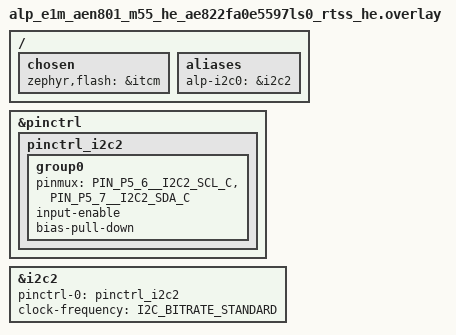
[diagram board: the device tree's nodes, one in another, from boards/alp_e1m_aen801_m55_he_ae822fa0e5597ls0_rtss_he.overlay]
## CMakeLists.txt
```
# SPDX-License-Identifier: Apache-2.0
#
# On-silicon I2C2 + EEPROM validation for the E1M-AEN801 (Alif Ensemble E8),
# scanning the SoC I2C2 DesignWare master bus and reading the on-module 24C128
# EEPROM @0x50 through the UPSTREAM Zephyr i2c_dw driver (Tier-1).  A RAM console
# carries the scan results + EEPROM hexdump + PASS/FAIL line.
#
# Standalone Zephyr app (no alp_project.py board.yaml flow): build with
#   ZEPHYR_BASE=<zephyr-base> west build \
#     -b alp_e1m_aen801_m55_he/ae822fa0e5597ls0/rtss_he <this-dir> -- \
#     "-DEXTRA_ZEPHYR_MODULES=<alp-sdk>;<hal_alif>"
# Zephyr applies boards/<fully-qualified-board>.overlay by itself.

cmake_minimum_required(VERSION 3.20)

find_package(Zephyr REQUIRED HINTS $ENV{ZEPHYR_BASE})
project(aen_i2c2_eeprom_regcheck LANGUAGES C)

target_sources(app PRIVATE src/main.c)
```

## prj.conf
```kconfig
# SPDX-License-Identifier: Apache-2.0
#
# Bench config for the I2C2 + EEPROM RAM-run on the E1M-AEN801 (Alif Ensemble
# E8).
#
# Console is the E1M edge UART0.

# --- Console -----------------------------------------------------------------
# Console: Alp UART console -- E1M edge UART0 (Alif UART5, P3_4/P3_5, 115200
# 8N1, NS16550), the E1M-AEN801 carrier console. The board _defconfig already
# selects it; we set it explicitly here so the example is self-describing.
CONFIG_SERIAL=y
CONFIG_CONSOLE=y
CONFIG_UART_CONSOLE=y
CONFIG_UART_INTERRUPT_DRIVEN=y
# Serial-less bench? Comment the four lines above and uncomment these to read
# 'ram_console_buf' over SWD instead:
# CONFIG_RAM_CONSOLE=y
# CONFIG_RAM_CONSOLE_BUFFER_SIZE=2048
# CONFIG_UART_CONSOLE=n
CONFIG_PRINTK=y

# --- I2C ---------------------------------------------------------------------
# The upstream i2c_dw driver (CONFIG_I2C_DW) self-selects `default y` from the
# okay'd "snps,designware-i2c" i2c2 node, so only the I2C subsystem itself needs
# turning on here.  PINCTRL is pulled in by the i2c2 pinctrl-0; set it for
# clarity.  ALP_SDK is not required for i2c_dw (Tier-1 upstream) -- left off to
# keep the image minimal.
CONFIG_I2C=y
CONFIG_PINCTRL=y

# Keep the image small + deterministic for a RAM-run.
CONFIG_LOG=n
```

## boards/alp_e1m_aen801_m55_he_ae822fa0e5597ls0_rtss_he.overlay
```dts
/*
 * Copyright (c) 2026 Alp Lab AB
 * SPDX-License-Identifier: Apache-2.0
 *
 * On-silicon I2C2 + EEPROM validation overlay for the E1M-AEN801 (Alif Ensemble
 * E8, M55-HE), bench RAM-run via J-Link.
 *
 * Wires the on-module 24C128 EEPROM bus.  The EEPROM's interface is selected by
 * bridge/DNP resistors onto SoC I2C2 (DesignWare master, upstream i2c_dw), pins
 * P5_6 SCL_C / P5_7 SDA_C -- NOT the slave-only LPI2C0 (which carries the
 * RTC/TMP on this board rev and is read-blocked).  Full master read+write via
 * upstream Zephyr's i2c_dw, per ADR 0017 (Tier-1 upstream-native).
 *
 * i2c2 node: i2c@49012000 (compatible "snps,designware-i2c", IRQ 134) per the
 * AE822 DFP device header.
 *
 * The pinctrl group below is copied VERBATIM from the aen-eeprom-manifest
 * overlay -- the input-enable + bias-pull-down pair is BENCH-VALIDATED on the E8
 * (2026-06-15).  Do NOT "correct" bias-pull-down to bias-pull-up: see the
 * group's own comment below for why -- alp-sdk#2046 corrected the reason
 * given here previously (pinctrl_soc.h does not invert the pull-direction
 * encoding).
 */
#include <zephyr/dt-bindings/pinctrl/alif-ensemble-pinctrl.h>
#include <zephyr/dt-bindings/i2c/i2c.h>

/*
 * MANDATORY bench RAM-run retarget: run from ITCM so J-Link can loadbin+run
 * without programming MRAM, and drop the MCUboot code-partition fixup.
 */
/ {
	chosen {
		/* PATH-REFERENCE form (&itcm), NOT the <&itcm> phandle-array form:
		 * the phandle-array form yields CONFIG_FLASH_SIZE=0 and the image
		 * overflows the (empty) FLASH region at link time. */
		zephyr,flash = &itcm;
		/delete-property/ zephyr,code-partition;
	};

	aliases {
		alp-i2c0 = &i2c2;
	};
};

&pinctrl {
	pinctrl_i2c2: pinctrl_i2c2 {
		group0 {
			pinmux = <PIN_P5_6__I2C2_SCL_C>, <PIN_P5_7__I2C2_SDA_C>;
			/* I2C pad config -- BENCH-VALIDATED on the E8 (2026-06-15) and
			 * matching Alif's own reference i2c pinctrl (sdk-alif
			 * common/ensemble-pinctrl.dtsi: read-enable=1 +
			 * driver-state-control=2):
			 *   input-enable    -> pad REN bit: the i2c_dw controller MUST be
			 *                      able to SENSE SDA/SCL or it reads every
			 *                      address as a NACK (no ACK detect). Without
			 *                      this the EEPROM never responds.
			 *   bias-pull-down  -> upstream pinctrl_soc.h encodes the pad
			 *                      driver-state-control (DSC) field as DSC=2
			 *                      from bias-pull-down, a REAL pull-down --
			 *                      exactly Alif's reference value for I2C, and
			 *                      NOT an inverted encoding: pinctrl_soc.h's
			 *                      ALIF_PINCTRL_BIAS_CFG() macro (lines 44-48)
			 *                      maps bias-pull-up -> DSC=1 and
			 *                      bias-pull-down -> DSC=2 unconditionally,
			 *                      matching the field comment at line 24.  A
			 *                      real pull-down is harmless here because the
			 *                      EVK carrier's R137/R144 pull-ups are stuffed
			 *                      on this bus and dominate a weak internal
			 *                      one.  Switching to bias-pull-up was earlier
			 *                      reported to give a dead bus, blamed on that
			 *                      (nonexistent) inversion -- the dead-bus
			 *                      report is therefore UNCONFIRMED, not
			 *                      disproven, absent a fresh bench trial; it is
			 *                      not evidence either way.
			 * Do NOT "correct" bias-pull-down to bias-pull-up: it is the
			 * bench-validated, correct-as-emitted value regardless of which
			 * reading is right (alp-sdk#2046).
			 */
			input-enable;
			bias-pull-down;
		};
	};
};

&i2c2 {
	status = "okay";
	pinctrl-0 = <&pinctrl_i2c2>;
	pinctrl-names = "default";
	/* 100 kHz: bench-validated; the on-module bus has no fast-mode margin
	 * unless external pull-ups are stuffed. */
	clock-frequency = <I2C_BITRATE_STANDARD>;
};
```

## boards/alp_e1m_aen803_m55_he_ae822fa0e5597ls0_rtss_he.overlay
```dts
/*
 * Copyright (c) 2026 Alp Lab AB
 * SPDX-License-Identifier: Apache-2.0
 *
 * On-silicon I2C2 + EEPROM validation overlay for the E1M-AEN803 (Alif Ensemble
 * E8, M55-HE), bench RAM-run via J-Link.
 *
 * Wires the on-module 24C128 EEPROM bus.  The EEPROM's interface is selected by
 * bridge/DNP resistors onto SoC I2C2 (DesignWare master, upstream i2c_dw), pins
 * P5_6 SCL_C / P5_7 SDA_C -- NOT the slave-only LPI2C0 (which carries the
 * RTC/TMP on this board rev and is read-blocked).  Full master read+write via
 * upstream Zephyr's i2c_dw, per ADR 0017 (Tier-1 upstream-native).
 *
 * i2c2 node: i2c@49012000 (compatible "snps,designware-i2c", IRQ 134) per the
 * AE822 DFP device header.
 *
 * The pinctrl group below is copied VERBATIM from the aen-eeprom-manifest
 * overlay -- the input-enable + bias-pull-down pair is BENCH-VALIDATED on the E8
 * (2026-06-15).  Do NOT "correct" bias-pull-down to bias-pull-up: see the
 * group's own comment below for why -- alp-sdk#2046 corrected the reason
 * given here previously (pinctrl_soc.h does not invert the pull-direction
 * encoding).
 */
#include <zephyr/dt-bindings/pinctrl/alif-ensemble-pinctrl.h>
#include <zephyr/dt-bindings/i2c/i2c.h>

/*
 * MANDATORY bench RAM-run retarget: run from ITCM so J-Link can loadbin+run
 * without programming MRAM, and drop the MCUboot code-partition fixup.
 */
/ {
	chosen {
		/* PATH-REFERENCE form (&itcm), NOT the <&itcm> phandle-array form:
		 * the phandle-array form yields CONFIG_FLASH_SIZE=0 and the image
		 * overflows the (empty) FLASH region at link time. */
		zephyr,flash = &itcm;
		/delete-property/ zephyr,code-partition;
	};

	aliases {
		alp-i2c0 = &i2c2;
	};
};

&pinctrl {
	pinctrl_i2c2: pinctrl_i2c2 {
		group0 {
			pinmux = <PIN_P5_6__I2C2_SCL_C>, <PIN_P5_7__I2C2_SDA_C>;
			/* I2C pad config -- BENCH-VALIDATED on the E8 (2026-06-15) and
			 * matching Alif's own reference i2c pinctrl (sdk-alif
			 * common/ensemble-pinctrl.dtsi: read-enable=1 +
			 * driver-state-control=2):
			 *   input-enable    -> pad REN bit: the i2c_dw controller MUST be
			 *                      able to SENSE SDA/SCL or it reads every
			 *                      address as a NACK (no ACK detect). Without
			 *                      this the EEPROM never responds.
			 *   bias-pull-down  -> upstream pinctrl_soc.h encodes the pad
			 *                      driver-state-control (DSC) field as DSC=2
			 *                      from bias-pull-down, a REAL pull-down --
			 *                      exactly Alif's reference value for I2C, and
			 *                      NOT an inverted encoding: pinctrl_soc.h's
			 *                      ALIF_PINCTRL_BIAS_CFG() macro (lines 44-48)
			 *                      maps bias-pull-up -> DSC=1 and
			 *                      bias-pull-down -> DSC=2 unconditionally,
			 *                      matching the field comment at line 24.  A
			 *                      real pull-down is harmless here because the
			 *                      EVK carrier's R137/R144 pull-ups are stuffed
			 *                      on this bus and dominate a weak internal
			 *                      one.  Switching to bias-pull-up was earlier
			 *                      reported to give a dead bus, blamed on that
			 *                      (nonexistent) inversion -- the dead-bus
			 *                      report is therefore UNCONFIRMED, not
			 *                      disproven, absent a fresh bench trial; it is
			 *                      not evidence either way.
			 * Do NOT "correct" bias-pull-down to bias-pull-up: it is the
			 * bench-validated, correct-as-emitted value regardless of which
			 * reading is right (alp-sdk#2046).
			 */
			input-enable;
			bias-pull-down;
		};
	};
};

&i2c2 {
	status = "okay";
	pinctrl-0 = <&pinctrl_i2c2>;
	pinctrl-names = "default";
	/* 100 kHz: bench-validated; the on-module bus has no fast-mode margin
	 * unless external pull-ups are stuffed. */
	clock-frequency = <I2C_BITRATE_STANDARD>;
};
```

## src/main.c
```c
/*
 * Copyright (c) 2026 Alp Lab AB
 * SPDX-License-Identifier: Apache-2.0
 *
 * On-silicon I2C2 + EEPROM validation for the E1M-AEN801 (Alif Ensemble E8) over
 * the UPSTREAM DesignWare i2c_dw driver (ADR 0017 Tier-1, "snps,designware-i2c").
 *
 * What it proves
 * --------------
 * The SoC I2C2 master bus works end to end on silicon: bus arbitration, 7-bit
 * addressing, ACK detect, and a combined write-then-read (repeated-START)
 * transaction against the on-module 24C128 EEPROM.  Three steps:
 *
 *   1. SCAN the 7-bit address space 0x08..0x77 -- probe each address with a
 *      1-byte read and record which ones ACK.  Prints the populated addresses.
 *   2. confirm 0x50 (the 24C128's standard 7-bit address) is among them.
 *   3. read 16 bytes from EEPROM offset 0 via i2c_write_read(dev, 0x50,
 *      {0x00,0x00} (big-endian 2-byte word address), 2, buf, 16) and hexdump.
 *
 * The EEPROM reaches I2C2 (not BRD_I2C, SoC I2C0) via bridge/DNP resistors on
 * P5_6 SCL_C / P5_7 SDA_C -- the established board finding; see the overlay.
 *
 * PASS criteria: device ready AND 0x50 found in the scan AND i2c_write_read()
 * returns 0.  Content is NOT checked: a BLANK 24C128 reads all-0xff (coherent),
 * which is a PASS -- this test proves the bus + addressing + read PATH, not the
 * stored manifest.  (aen-eeprom-manifest decodes the content.)
 *
 * Console is the RAM buffer 'ram_console_buf' (see prj.conf); the bench UART is
 * not wired to USB.  BENCH-VALIDATION app -- not a customer teaching example.
 */

#include <zephyr/kernel.h>
#include <zephyr/device.h>
#include <zephyr/drivers/i2c.h>

/* i2c2 == i2c@49012000 (snps,designware-i2c), okay'd + pinctrl'd by the overlay. */
#define I2C2_NODE DT_NODELABEL(i2c2)

/* 24C128 standard 7-bit address. */
#define EEPROM_ADDR 0x50U

/* General-call (0x00..0x07) and reserved-high (0x78..0x7f) addresses are skipped
 * by the conventional scan window, matching Zephyr's i2c_scanner sample. */
#define SCAN_LO 0x08U
#define SCAN_HI 0x77U

static const struct device *const i2c2 = DEVICE_DT_GET(I2C2_NODE);

/* xxd-style 16-byte hexdump (single line here; len is 16). */
static void hex_dump(const uint8_t *buf, size_t len)
{
	printk("  0000  ");
	for (size_t i = 0; i < len; i++) {
		printk("%02x ", buf[i]);
	}
	printk(" |");
	for (size_t i = 0; i < len; i++) {
		uint8_t c = buf[i];

		printk("%c", (c >= 0x20 && c < 0x7f) ? c : '.');
	}
	printk("|\n");
}

int main(void)
{
	int          rc;
	uint8_t      dummy;
	bool         found_0x50 = false;
	unsigned int n_found    = 0U;

	printk("\n=== AEN801 I2C2 + EEPROM bench (i2c_dw / i2c2 @ 0x49012000) ===\n");

	/* 1. device readiness. */
	if (!device_is_ready(i2c2)) {
		printk("RESULT FAIL: i2c2 device not ready\n");
		return 0;
	}
	printk("i2c2 device ready\n");

	/* 2. bus scan: probe each 7-bit address with a 1-byte read; an ACK (rc==0)
	 *    means a device sits there.  A 1-byte read is the most portable probe
	 *    for i2c_dw -- a zero-length write is not universally honoured. */
	printk("scanning 0x%02x..0x%02x ...\n", SCAN_LO, SCAN_HI);
	for (uint16_t addr = SCAN_LO; addr <= SCAN_HI; addr++) {
		rc = i2c_read(i2c2, &dummy, 1U, addr);
		if (rc == 0) {
			printk("  ACK @ 0x%02x\n", addr);
			n_found++;
			if (addr == EEPROM_ADDR) {
				found_0x50 = true;
			}
		}
	}
	printk("scan done: %u device(s) responded; 0x50 %s\n",
	       n_found,
	       found_0x50 ? "PRESENT" : "MISSING");

	if (!found_0x50) {
		printk("RESULT FAIL: 24C128 @ 0x50 not found on I2C2 "
		       "(EEPROM populated?  bridge/DNP selecting I2C2?  pinctrl?)\n");
		return 0;
	}

	/* 3. read 16 bytes from EEPROM offset 0.  The 24C128 takes a 2-byte
	 *    BIG-ENDIAN word address; i2c_write_read issues write(addr)+repeated-
	 *    START+read in one transaction. */
	uint8_t word_addr[2] = { 0x00U, 0x00U };
	uint8_t buf[16];

	rc = i2c_write_read(i2c2, EEPROM_ADDR, word_addr, sizeof(word_addr), buf, sizeof(buf));
	printk("i2c_write_read(0x50, off=0, 16B) rc=%d\n", rc);
	if (rc != 0) {
		printk("RESULT FAIL: i2c_write_read rc=%d\n", rc);
		return 0;
	}

	printk("EEPROM[0..15]:\n");
	hex_dump(buf, sizeof(buf));

	/* 4. verdict: bus + addressing + read path all worked.  All-0xff (blank
	 *    EEPROM) is still a PASS -- the test proves the PATH, not the content. */
	printk("RESULT PASS: I2C2 master scan found 0x50 and read 16B "
	       "(bus + addressing + repeated-START read OK; content not checked)\n");

	return 0;
}
```
